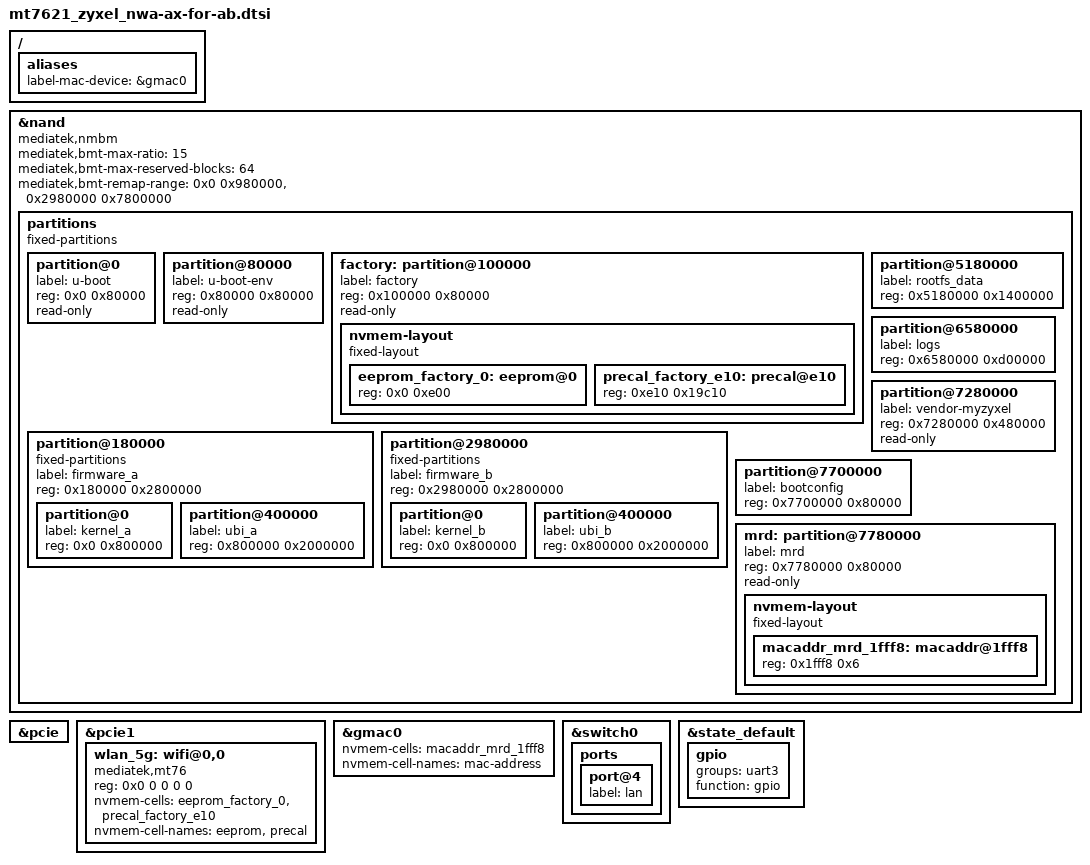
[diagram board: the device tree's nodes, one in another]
#include "mt7621.dtsi"

#include <dt-bindings/gpio/gpio.h>
#include <dt-bindings/input/input.h>

/ {
	aliases {
		label-mac-device = &gmac0;
	};
};

&nand {
	status = "okay";

	mediatek,nmbm;
	mediatek,bmt-max-ratio = <15>;
	mediatek,bmt-max-reserved-blocks = <64>;
	mediatek,bmt-remap-range =
		<0x0 0x980000>,
		<0x2980000 0x7800000>;

	partitions {
		compatible = "fixed-partitions";
		#address-cells = <1>;
		#size-cells = <1>;

		partition@0 {
			label = "u-boot";
			reg = <0x0 0x80000>;
			read-only;
		};

		partition@80000 {
			label = "u-boot-env";
			reg = <0x80000 0x80000>;
			read-only;
		};

		factory: partition@100000 {
			label = "factory";
			reg = <0x100000 0x80000>;
			read-only;

			nvmem-layout {
				compatible = "fixed-layout";
				#address-cells = <1>;
				#size-cells = <1>;

				eeprom_factory_0: eeprom@0 {
					reg = <0x0 0xe00>;
				};

				precal_factory_e10: precal@e10 {
					reg = <0xe10 0x19c10>;
				};
			};
		};

		partition@180000 {
			label = "firmware_a";
			reg = <0x180000 0x2800000>;

			compatible = "fixed-partitions";
			#address-cells = <1>;
			#size-cells = <1>;

			partition@0 {
				label = "kernel_a";
				reg = <0x0 0x800000>;
			};

			partition@400000 {
				label = "ubi_a";
				reg = <0x800000 0x2000000>;
			};
		};

		partition@2980000 {
			label = "firmware_b";
			reg = <0x2980000 0x2800000>;

			compatible = "fixed-partitions";
			#address-cells = <1>;
			#size-cells = <1>;

			partition@0 {
				label = "kernel_b";
				reg = <0x0 0x800000>;
			};

			partition@400000 {
				label = "ubi_b";
				reg = <0x800000 0x2000000>;
			};
		};

		partition@5180000 {
			label = "rootfs_data";
			reg = <0x5180000 0x1400000>;
		};

		partition@6580000 {
			label = "logs";
			reg = <0x6580000 0xd00000>;
		};

		partition@7280000 {
			label = "vendor-myzyxel";
			reg = <0x7280000 0x480000>;
			read-only;
		};

		partition@7700000 {
			label = "bootconfig";
			reg = <0x7700000 0x80000>;
		};

		mrd: partition@7780000 {
			label = "mrd";
			reg = <0x7780000 0x80000>;
			read-only;

			nvmem-layout {
				compatible = "fixed-layout";
				#address-cells = <1>;
				#size-cells = <1>;

				macaddr_mrd_1fff8: macaddr@1fff8 {
					reg = <0x1fff8 0x6>;
				};
			};
		};
	};
};

&pcie {
	status = "okay";
};

&pcie1 {
	wlan_5g: wifi@0,0 {
		reg = <0x0 0 0 0 0>;
		compatible = "mediatek,mt76";

    nvmem-cells = <&eeprom_factory_0>, <&precal_factory_e10>;
		nvmem-cell-names = "eeprom", "precal";

		/* MAC-Address set in userspace */
	};
};

&gmac0 {
	nvmem-cells = <&macaddr_mrd_1fff8>;
	nvmem-cell-names = "mac-address";
};

&switch0 {
	ports {
		port@4 {
			status = "okay";
			label = "lan";
		};
	};
};

&state_default {
	gpio {
		groups = "uart3";
		function = "gpio";
	};
};
